# YTM32B1HA0 register map
Vendor: YTMicro; File version: 1.0
CPU: little endian, MPU, FPU, 2 interrupt priority bits
Registers are 32-bit, read-write, reset 0x0 unless marked. A register's access mark holds for its fields unless they carry their own. Offsets are from the block's base; [hi:lo] are bit positions; {n}, {i} and the like mark numbered series.

## EMU — ECC Management Unit
Base 0x401C8000; register names take the prefix EMU_
0x00 EIGCR
  [0] GEN — This bit will enable or disable all error injection functions. Write 0x89abcdef will enable this function. Read 0 means, global error injection is disabled Read 1 means, global error injection is enabled
0x04 EICHCR
  [5:0] CHEN — This field enable or disable channel n error injection function. Enable channel n error injection function should enable this field and EIGCR[GEN]. Any write to EICHDn_ADDR, EICHDn_CHKBIT, EICHDn_DATAH/L register will clear this field. 0b - Channel n error injection is disabled 1b - Channel n error injection is enabled
{0x10+0x10*i} EICHD{i}_ADDR (i=0..5)
  [31:0] ADDR — This field defines which address will be injected error when read access. when the ADDR is not 0, error will be injected according to this field's value. If ADDR is 0, Error will be injected at all read access.
{0x14+0x10*i} EICHD{i}_CHKBIT (i=0..5)
  [7:0] CHKBIT — This field defines a bit-mapped mask that specifies whether the corresponding bit of the checkbit bus from the target on-chip memory should be inverted or remain unmodified. ewline 0b - The corresponding bit of the checkbit bus remains unmodified. ewline 1b - The corresponding bit of the checkbit bus is inverted.
{0x18+0x10*i} EICHD{i}_DATAL (i=0..5)
  [31:0] DATAL — This field defines a bit-mapped mask that specifies whether the corresponding bit of the read data bus from the target on-chip memory should be inverted or remain unmodified. ewline 0b - The corresponding bit of the databit bus remains unmodified. ewline 1b - The corresponding bit of the databit bus is inverted.
{0x1C+0x10*i} EICHD{i}_DATAH (i=0..5)
  [31:0] DATAH — This field defines a bit-mapped mask that specifies whether the corresponding bit of the read data bus from the target on-chip memory should be inverted or remain unmodified. ewline 0b - The corresponding bit of the databit bus remains unmodified. ewline 1b - The corresponding bit of the databit bus is inverted.
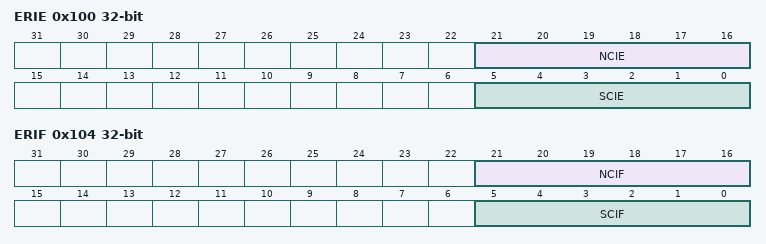
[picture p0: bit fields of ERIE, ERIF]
0x100 ERIE
  [21:16] NCIE — Non-Correctable error interrupt enable. 0b - Channel n Non-Correctable Error interrupt is disabled 1b - Channel n Non-Correctable Error interrupt is enabled
  [5:0] SCIE — Single correctable error interrupt enable 0b - Channel n Single Correctable Error interrupt is disabled 1b - Channel n Single Correctable Error interrupt is enabled
0x104 ERIF
  [21:16] NCIF — Non-Correctable error interrupt flag. NCIF flag is kept when software reset but cleared when POR. 0b - Channel n Non-Correctable Error interrupt not detected 1b - Channel n Non-Correctable Error interrupt detected
  [5:0] SCIF — Single Correctable error interrupt flag. SCIF flag is kept when software reset but cleared when POR. 0b - Channel n Single Correctable Error interrupt not detected 1b - Channel n Single Correctable Error interrupt detected
{0x110+0x10*i} ERINFO{i}_ADDR ro (i=0..5)
  [31:0] ADDR — This field contains the faulting system address of the last recorded ECC event on on-chip memories.
{0x114+0x10*i} ERINFO{i}_SYND ro (i=0..5)
  [7:0] SYNDROME — This field contains the syndrome of the last recorded ECC event on on-chip memories. For 32 bit memory, just low 7 bits([6:0]) is effective. For 64 bit memory, the 8 bits ([7:0]) is effective.
{0x118+0x10*i} ERINFO{i}_CNT wo (i=0..5)
  [7:0] CNT rw — For each correctable error event, the EMU increments this field's error count value until the counter reaches its maximum value 0xFF. CNT will not change once it reaches 0xFF and will not wrap even if error occurs. Read this field to determine the correctable error count value so far. Write zero to this field to reset the counter. Writing non-zero (or partial zero) values has no effect.
